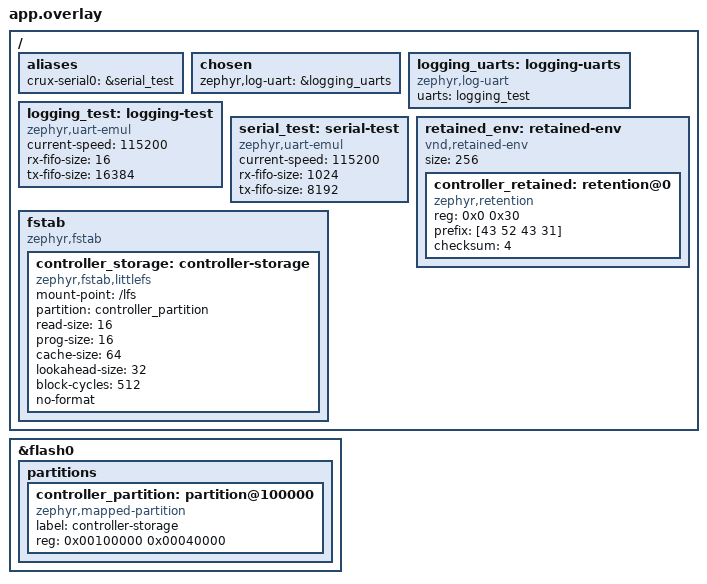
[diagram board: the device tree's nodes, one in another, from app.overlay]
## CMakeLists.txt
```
# SPDX-License-Identifier: Apache-2.0

# The storage scenario of the controller framework on native_sim: LittleFS on the flash simulator, the
# size limit of the application data root (criterion 24), the factory reset with a power cut before
# the erase (criterion 42) and failed logins (criterion 43). The scenario's main() is the application:
# it passes its own descriptor and writes under its data root through Crux File, as a product would.
# This file names no source or include directory of the framework.

cmake_minimum_required(VERSION 3.20.0)
list(APPEND DTS_ROOT "${CMAKE_CURRENT_LIST_DIR}/../common")
find_package(Zephyr REQUIRED HINTS $ENV{ZEPHYR_BASE})
project(controller_framework_storage_native_sim LANGUAGES C)

if(NOT CONFIG_BOARD_NATIVE_SIM OR NOT CONFIG_FAKE_ENTROPY_NATIVE_SIM)
    message(FATAL_ERROR "This scenario is restricted to native_sim: its entropy source is a test source")
endif()
if(NOT CONFIG_CRUX_CONTROLLER_FRAMEWORK_SUPERVISION OR NOT CONFIG_CRUX_CONTROLLER_FRAMEWORK_REBOOT
   OR NOT CONFIG_CRUX_CONTROLLER_FRAMEWORK_MANAGEMENT OR NOT CONFIG_CRUX_FILE_SIMULATOR
   OR NOT CONFIG_FILE_SYSTEM_LITTLEFS OR NOT CONFIG_CRUX_SYSTEM_NATIVE_SIM_WATCHDOG)
    message(FATAL_ERROR "The storage scenario needs supervision, Crux Reboot, web management, LittleFS "
                        "on the flash simulator and the simulated watchdog")
endif()

target_sources(app PRIVATE src/test_storage.c ../common/scenario.c ../common/retained_env.c
    ../common/https.c)
target_include_directories(app PRIVATE ../common)
# crux::security_event: the scenario waits for the event drain before a line that follows events.
target_link_libraries(app PRIVATE controller::framework crux::access crux::file crux::config_service
    crux::credential_store crux::logging crux::security_event)
# Test-only: Crux's account erase resolves to __wrap_crux_credential_erase_accounts in
# src/test_storage.c, which cuts the power in boot 1, before anything is erased, and calls Crux's
# erase in the other boots. GNU ld's --wrap, as the application scenario wraps the TLS start.
target_link_options(app PUBLIC -Wl,--wrap=crux_credential_erase_accounts)
# Test-only: the session creation of Crux Access for channel adapters, which no product reaches, so
# that the test can make an account of the read-only role and save the configuration in the
# administrator's name. PRIVATE to this test image, as in the application scenario.
target_include_directories(app PRIVATE "${ZEPHYR_CRUX_MODULE_DIR}/components/access/adapter")
controller_framework_image()
```

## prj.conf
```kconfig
# SPDX-License-Identifier: Apache-2.0
# The storage scenario of the controller framework on native_sim: LittleFS on the flash simulator,
# the size limit of the application data root (criterion 24), the factory reset with a power cut
# before the erase (criterion 42) and failed logins (criterion 43). Its other values are those of the
# application scenario (tests/framework/application/prj.conf), with no start prerequisite, because
# this scenario degrades storage on purpose.
CONFIG_CRUX_CONTROLLER_FRAMEWORK=y
CONFIG_SNTP=y
CONFIG_CRUX_CONTROLLER_TIME_SERVER="127.0.0.1"

CONFIG_CRUX_SERIAL=y
CONFIG_CRUX_CLI=y
CONFIG_CRUX_CLI_CONSOLE=y
CONFIG_CRUX_CLI_CONSOLE_PRIORITY=11
CONFIG_UART_INTERRUPT_DRIVEN=y
CONFIG_UART_USE_RUNTIME_CONFIGURE=y

CONFIG_STD_C17=y
CONFIG_EMUL=y
CONFIG_UART_EMUL=y
CONFIG_IRQ_OFFLOAD=y
# The web adapter refuses the external libc of native_sim; the management scenario runs on picolibc.
CONFIG_PICOLIBC=y
# One thread of the test runs the start sequence (key generation, signing, the format of the RAM
# disk) and the TLS client. Not measured.
CONFIG_MAIN_STACK_SIZE=32768
CONFIG_HEAP_MEM_POOL_SIZE=32768

# The Mbed TLS profile of app/conf/management.conf, as a copy: this scenario has no Kconfig of the product,
# as in the management scenario. The heap is larger than the product's 120,000 bytes,
# because the TLS client of the test runs in the same process and takes up to one more connection
# and its own handshake. The product declares 120,000 bytes for three server connections of 34,912
# bytes, a handshake of 3,576 bytes and the other PSA users, and 180,000 leaves about 25,000 bytes
# over the worst concurrent case that this process can reach. A paper figure, not measured.
CONFIG_MBEDTLS=y
CONFIG_MBEDTLS_PSA_CRYPTO_C=y
CONFIG_PSA_CRYPTO_PROVIDER_MBEDTLS=y
CONFIG_MBEDTLS_ENABLE_HEAP=y
CONFIG_MBEDTLS_HEAP_SIZE=180000
CONFIG_MBEDTLS_SSL_IN_CONTENT_LEN=16384
CONFIG_MBEDTLS_SSL_OUT_CONTENT_LEN=16384
CONFIG_MBEDTLS_SSL_PROTO_TLS1_2=y
CONFIG_MBEDTLS_SSL_PROTO_TLS1_3=y
CONFIG_MBEDTLS_SSL_TLS1_3_KEY_EXCHANGE_MODE_EPHEMERAL_ENABLED=y
CONFIG_MBEDTLS_KEY_EXCHANGE_ECDHE_ECDSA_ENABLED=y
CONFIG_MBEDTLS_CIPHERSUITE_TLS_ECDHE_ECDSA_WITH_AES_128_GCM_SHA256=y
CONFIG_MBEDTLS_CIPHERSUITE_TLS1_3_AES_128_GCM_SHA256=y
CONFIG_PSA_WANT_ALG_SHA_256=y
CONFIG_PSA_WANT_ECC_SECP_R1_256=y
CONFIG_PSA_WANT_ALG_ECDSA=y
CONFIG_PSA_WANT_ALG_ECDH=y
CONFIG_PSA_WANT_ALG_GCM=y
CONFIG_PSA_WANT_KEY_TYPE_AES=y
CONFIG_PSA_WANT_ALG_HMAC=y
CONFIG_PSA_WANT_KEY_TYPE_HMAC=y
CONFIG_PSA_WANT_ALG_HKDF=y
CONFIG_PSA_WANT_ALG_PBKDF2_HMAC=y
CONFIG_PSA_WANT_ALG_TLS12_PRF=y
CONFIG_PSA_WANT_KEY_TYPE_ECC_PUBLIC_KEY=y
CONFIG_PSA_WANT_KEY_TYPE_ECC_KEY_PAIR_IMPORT=y
CONFIG_PSA_WANT_KEY_TYPE_ECC_KEY_PAIR_EXPORT=y
CONFIG_PSA_WANT_KEY_TYPE_ECC_KEY_PAIR_GENERATE=y
CONFIG_PSA_WANT_KEY_TYPE_ECC_KEY_PAIR_DERIVE=y
CONFIG_MBEDTLS_PK_WRITE_C=y
CONFIG_CRUX_PSA_THREADING=y

# The Crux services, as in app/conf/management.conf. The module selects Thread, Sync and Time for them.
CONFIG_CRUX_ACCESS=y
CONFIG_CRUX_CONFIG_SERVICE=y
CONFIG_CRUX_MGMT_STATUS=y
CONFIG_CRUX_TLS_CERTIFICATE=y
CONFIG_CRUX_WEB=y
CONFIG_CRUX_WEB_SESSION=y
CONFIG_CRUX_WEB_MANAGEMENT=y
CONFIG_CRUX_SYSTEM=y
CONFIG_CRUX_NETIF=y
CONFIG_WATCHDOG=y
CONFIG_HWINFO=y
CONFIG_REBOOT=y

# The listener binds the loopback address, and the TLS client of the test is in the same process. The
# listener opens on Zephyr's own thread, so the client retries its connect.
CONFIG_CRUX_WEB_PORT=443
CONFIG_CRUX_WEB_BIND_ADDRESS="127.0.0.1"
CONFIG_CRUX_WEB_BACKLOG=4
CONFIG_HTTP_SERVER_MAX_CLIENTS=3
CONFIG_HTTP_SERVER_STACK_SIZE=16384
CONFIG_CRUX_WEB_SESSION_WORKER_PRIORITY=11
CONFIG_CRUX_WEB_MANAGEMENT_WORKER_PRIORITY=11
CONFIG_CRUX_SECURITY_EVENT_DRAIN_PRIORITY=11

# The simulator's fake entropy source: test-only, so nothing made here is a secret.
CONFIG_ENTROPY_GENERATOR=y

# Crux File on LittleFS over the flash simulator of native_sim (CONFIG_CRUX_FILE_SIMULATOR), which
# keeps its bytes in a file of the host, so the volume survives the restart of the simulated process
# (criteria 24 and 42 on LittleFS). The first boot finds the flash blank, and the zone formats it.
CONFIG_FLASH=y
CONFIG_FLASH_MAP=y
CONFIG_FLASH_SIMULATOR=y
CONFIG_FILE_SYSTEM=y
CONFIG_FILE_SYSTEM_MKFS=y
CONFIG_FILE_SYSTEM_LITTLEFS=y
CONFIG_FS_LITTLEFS_NUM_FILES=8
CONFIG_CRUX_FILE_SIMULATOR=y

# The network: Zephyr's loopback interface, TCP and the TLS socket layer, with no host network.
CONFIG_NETWORKING=y
CONFIG_NET_IPV4=y
CONFIG_NET_IPV6=n
CONFIG_NET_TCP=y
CONFIG_NET_UDP=y
CONFIG_NET_SOCKETS=y
CONFIG_NET_DRIVERS=y
CONFIG_NET_LOOPBACK=y
CONFIG_NET_SOCKETS_SOCKOPT_TLS=y
CONFIG_TLS_CREDENTIALS=y
CONFIG_TLS_MAX_CREDENTIALS_NUMBER=4
CONFIG_NET_SOCKETS_TLS_MAX_CONTEXTS=6
CONFIG_ZVFS_OPEN_MAX=48
CONFIG_ZVFS_POLL_MAX=24
CONFIG_ZVFS_EVENTFD=y
CONFIG_NET_MAX_CONTEXTS=32
CONFIG_NET_MAX_CONN=32
CONFIG_NET_PKT_RX_COUNT=64
CONFIG_NET_PKT_TX_COUNT=64
CONFIG_NET_BUF_RX_COUNT=256
CONFIG_NET_BUF_TX_COUNT=256

# Crux Logging writes to an emulated UART, so that the test can read what it wrote.
CONFIG_CRUX_LOGGING=y
CONFIG_SERIAL=y
CONFIG_LOG=y
CONFIG_LOG_MODE_DEFERRED=y
CONFIG_LOG_MODE_OVERFLOW=n
CONFIG_LOG_BLOCK_IN_THREAD=n
CONFIG_LOG_PROCESS_THREAD=y
CONFIG_LOG_PROCESS_THREAD_STACK_SIZE=2048
CONFIG_LOG_PROCESS_THREAD_CUSTOM_PRIORITY=y
CONFIG_LOG_PROCESS_THREAD_PRIORITY=14
CONFIG_LOG_BUFFER_SIZE=8192
CONFIG_LOG_MAX_LEVEL=4
CONFIG_LOG_DEFAULT_LEVEL=0
CONFIG_LOG_RUNTIME_FILTERING=n
CONFIG_LOG_BACKEND_UART=y
CONFIG_LOG_BACKEND_NATIVE_POSIX=n
CONFIG_LOG_BACKEND_UART_ASYNC=n
CONFIG_LOG_PRINTK=n
CONFIG_SHELL_LOG_BACKEND=n
CONFIG_LOG_BACKEND_SHOW_LEVEL=y
CONFIG_LOG_BACKEND_CRLF_NONE=n
CONFIG_THREAD_MONITOR=y
CONFIG_THREAD_NAME=y
# An image with Crux management must not enable the Zephyr shell.
CONFIG_SHELL=n

# Health supervision with the simulated watchdog and the retained region, short timeouts so that
# the scenario stays short, and fault injection. The retained memory and the retention area are
# built without their mutexes, as the base image builds them, because the fatal error handler
# writes the region.
CONFIG_TASK_WDT=y
CONFIG_TASK_WDT_HW_FALLBACK=n
CONFIG_CRUX_REBOOT=y
CONFIG_CRUX_SYSTEM_NATIVE_SIM_WATCHDOG=y
CONFIG_NATIVE_SIM_REBOOT=y
CONFIG_RETAINED_MEM=y
CONFIG_RETAINED_MEM_MUTEX_FORCE_DISABLE=y
CONFIG_RETENTION=y
CONFIG_RETENTION_MUTEX_FORCE_DISABLE=y
CONFIG_CRUX_CONTROLLER_FRAMEWORK_FAULT_INJECTION=y
CONFIG_CRUX_CONTROLLER_WATCHDOG_TIMEOUT_MS=2000
CONFIG_CRUX_CONTROLLER_SUPERVISOR_PERIOD_MS=500
CONFIG_CRUX_CONTROLLER_DEADLINE_COMMAND_LINE_MS=2000
CONFIG_CRUX_CONTROLLER_STABLE_PERIOD_S=3600
CONFIG_MAIN_THREAD_PRIORITY=8

# --- The application ------------------------------------------------------------------------------
# The scenario's own descriptor, with the deadlines of the application scenario and no start
# prerequisite.
CONFIG_CRUX_CONTROLLER_DEADLINE_INIT_MS=2000
CONFIG_CRUX_CONTROLLER_DEADLINE_APPLICATION_MS=1500
CONFIG_CRUX_CONTROLLER_DEADLINE_STOP_MS=1000
CONFIG_CRUX_CONTROLLER_APP_THREAD_STACK=4096
# The run has one fault reset (the power cut); the threshold keeps every boot out of safe mode.
CONFIG_CRUX_CONTROLLER_SAFE_MODE_THRESHOLD=10

# A small limit of the application data root, so that boot 1 fills it with a few files (criterion 24,
# gap C15); a value other than the default (criterion 27).
CONFIG_CRUX_CONTROLLER_APP_ROOT_MAX_BYTES=16384
```

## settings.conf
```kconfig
# SPDX-License-Identifier: Apache-2.0
# A fragment for the build test of criterion 32 (check base-settings-file-sources): Crux's Settings
# File provider of Configuration on the LittleFS volume of the storage scenario. The check configures
# the scenario with it and reads which Settings File sources the build compiles; nothing runs it,
# because the framework does not initialise the provider yet (gap C22).
CONFIG_SETTINGS=y
CONFIG_SETTINGS_FILE=y
CONFIG_SETTINGS_FILE_PATH="/lfs/settings/cfg"
CONFIG_CRUX_CONFIGURATION_SETTINGS_FILE_ANY_FS=y
```

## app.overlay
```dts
/* The devicetree of the storage scenario. As in the application scenario
 * (tests/framework/application/app.overlay): a retained region over the test-only retained memory of
 * ../common, which keeps its bytes across a restart of the simulated process; Crux Logging on an
 * emulated UART that the test reads; and the Crux serial console on a second emulated UART through
 * the alias crux-serial0, which the test types into. Unlike there, the volume of the entry
 * controller_storage is LittleFS on the flash simulator, which keeps its bytes in a file of the host,
 * so the volume survives the restart of the simulated process; the first boot finds it blank. */
/ {
    aliases { crux-serial0 = &serial_test; };
    chosen { zephyr,log-uart = &logging_uarts; };
    logging_uarts: logging-uarts {
        compatible = "zephyr,log-uart";
        uarts = <&logging_test>;
    };
    logging_test: logging-test {
        compatible = "zephyr,uart-emul";
        current-speed = <115200>;
        rx-fifo-size = <16>;
        tx-fifo-size = <16384>;
        status = "okay";
    };
    serial_test: serial-test {
        compatible = "zephyr,uart-emul";
        current-speed = <115200>;
        rx-fifo-size = <1024>;
        /* The status command writes more than 1 KiB at once, and the emulated UART drops the bytes
         * that do not fit (uart_emul_poll_out in Zephyr's drivers/serial/uart_emul.c). */
        tx-fifo-size = <8192>;
        status = "okay";
    };

    retained_env: retained-env {
        compatible = "vnd,retained-env";
        size = <256>;
        status = "okay";
        #address-cells = <1>;
        #size-cells = <1>;

        controller_retained: retention@0 {
            compatible = "zephyr,retention";
            status = "okay";
            reg = <0x0 0x30>;
            prefix = [43 52 43 31];
            checksum = <4>;
        };
    };

    fstab {
        compatible = "zephyr,fstab";
        controller_storage: controller-storage {
            compatible = "zephyr,fstab,littlefs";
            mount-point = "/lfs";
            partition = <&controller_partition>;
            read-size = <16>;
            prog-size = <16>;
            cache-size = <64>;
            lookahead-size = <32>;
            block-cycles = <512>;
            /* Never format on a failed mount: the zone formats only a blank volume, by its policy. */
            no-format;
        };
    };
};

/* 256 KiB in the free upper half of the simulated 2 MiB flash (as Crux's tests/native/file_littlefs
 * places its partition). */
&flash0 {
    partitions {
        controller_partition: partition@100000 {
            compatible = "zephyr,mapped-partition";
            label = "controller-storage";
            reg = <0x00100000 0x00040000>;
        };
    };
};
```

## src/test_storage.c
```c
/* SPDX-License-Identifier: Apache-2.0 */

/* The storage scenario of the controller framework on native_sim. One run, three boots, on LittleFS
 * over the flash simulator, whose file on the host keeps the volume across the restarts. main() is
 * the application: it passes its own descriptor and writes under its data root through Crux File,
 * as a product would. Each boot prints what the console harness of testcase.yaml matches, in order:
 *
 *   1. The blank volume is formatted. The first account is set up on the serial command line. The
 *      application fills its data root until Crux File refuses a write at the size limit; the
 * status service then shows storage degraded and a credential save (a second account) still
 * succeeds (criterion 24, gap C15; the parameter save needs a save provider, gap C22). The
 *      read-only account does not see the factory reset command; the administrator changes its
 *      role and resets its password, then runs the factory reset, and the power is cut before the
 *      account erase (criterion 42). Crux's security events of these steps (first-account setup,
 *      login, account creation, logout, role change and password reset) are in the log before the
 *      scenario line that follows them (criterion 44, without persistence).
 *   2. The accounts are still in place: the administrator logs in. The data root is empty. The
 *      factory reset runs again and completes.
 *   3. First-account setup is open again, the data root is empty, and the device identity was kept.
 *      Wrong passwords on the serial command line and on web management are delayed and recorded as
 *      security events (criterion 43).
 */

#include <stdbool.h>
#include <stddef.h>
#include <stdint.h>
#include <stdio.h>
#include <string.h>

#include <controller/framework.h>
#include <crux/access.h>
#include <crux/config_service.h>
#include <crux/credential_store.h>
#include <crux/file.h>
#include <crux/security_event.h>

#include <crux_access_adapter.h>
#include <zephyr/kernel.h>
#include <zephyr/sys/reboot.h>

#include "https.h"
#include "scenario.h"

#define USER "operator"
#define PASSWORD "storage scenario password"
#define READER "reader"
#define READER_ROLE "read-only"
#define READER_PASSWORD "storage scenario reader"
#define READER_RESET_PASSWORD "storage scenario reader reset"
#define WRONG_PASSWORD "not the password at all"
/* The data root (CONFIG_CRUX_CONTROLLER_APP_ROOT_MAX_BYTES is 16384 here) and one LittleFS block.
 */
#define FILE_BYTES 4096u
#define FILES_MAX 16
#define STATUS_POLLS 20
#define LOGIN_ATTEMPTS 10
#define DRAIN_POLLS 200

static int boot;
static controller_app_context_t *app_context;

static void fail(const char *what)
{
    char text[160];

    (void)snprintf(text, sizeof text, "storage scenario FAILED: %s", what);
    scenario_say(text);
}

static bool expect(const char *text)
{
    if (!scenario_console_expect(text)) {
        fail(text);
        return false;
    }
    return true;
}

/* --- the application: four entries that do nothing but succeed --- */

static int app_init(controller_app_context_t *context)
{
    app_context = context;
    return 0;
}

static int app_start(controller_app_context_t *context)
{
    (void)context;
    return 0;
}

static int app_stop(controller_app_context_t *context, controller_app_stop_reason_t reason)
{
    (void)context;
    (void)reason;
    return 0;
}

static void app_safe_state(controller_app_context_t *context)
{
    (void)context;
}

static const controller_app_t app = {app_init, app_start, app_stop, app_safe_state, NULL};

/* --- the power cut of boot 1 --- */

crux_credential_result_t __real_crux_credential_erase_accounts(void);
crux_credential_result_t __wrap_crux_credential_erase_accounts(void);

/* Boot 1: the power goes before the erase writes anything; a restart of the simulated process
 * stands in for the cut (no marker is written, and the volume keeps what was written before). */
crux_credential_result_t __wrap_crux_credential_erase_accounts(void)
{
    if (boot == 1) {
        scenario_say("storage scenario: power cut before the account erase");
        sys_reboot(SYS_REBOOT_COLD);
    }
    return __real_crux_credential_erase_accounts();
}

/* Wait until Crux's drain thread has written every security event that the ring admitted, so the
 * next scenario line follows their log lines: scenario_say() flushes the log first. A report of
 * lost records also counts as a written line, so the written lines reach the admitted ones at
 * least. The counts wrap at 2^32, so their difference is compared as signed. */
static bool events_drained(void)
{
    for (int poll = 0; poll < DRAIN_POLLS; poll++) {
        crux_security_event_stats_t stats;

        if (crux_security_event_get_stats(&stats) == CRUX_OK &&
            (int32_t)(stats.delivered + stats.log_errors - stats.emitted) >= 0) {
            return true;
        }
        k_msleep(10);
    }
    fail("the security events to drain");
    return false;
}

/* --- the serial command line --- */

static bool login(const char *user, const char *password)
{
    if (!expect("login: ")) {
        return false;
    }
    scenario_console_type(user);
    if (!expect("password: ")) {
        return false;
    }
    scenario_console_type(password);
    return expect("> ");
}

static bool setup_first_account(void)
{
    if (!expect("login: ")) {
        return false;
    }
    scenario_console_type("!setup");
    if (!expect("new user: ")) {
        return false;
    }
    scenario_console_type(USER);
    if (!expect("password: ")) {
        return false;
    }
    scenario_console_type(PASSWORD);
    if (!expect("repeat: ")) {
        return false;
    }
    scenario_console_type(PASSWORD);
    if (!expect("account created")) {
        return false;
    }
    return login(USER, PASSWORD);
}

static void logout(void)
{
    scenario_console_type("logout");
}

/* The storage health in the status service: the status command, until it shows the value. */
static bool storage_health_is(const char *value)
{
    char item[160];

    (void)snprintf(item, sizeof item,
                   "{\"name\":\"controller.health.storage\",\"status\":\"ok\",\"type\":\"text\","
                   "\"value\":\"%s\"}",
                   value);
    for (int poll = 0; poll < STATUS_POLLS; poll++) {
        scenario_console_type("status");
        if (scenario_console_expect(item)) {
            return expect("> ");
        }
        k_msleep(500);
    }
    fail(item);
    return false;
}

/* --- Crux Access in the administrator's name (no command makes a second account, gap C21) --- */

static bool admin_session(crux_access_session_t *session)
{
    const crux_access_origin_t origin = {CRUX_ACCESS_CHANNEL_SERIAL, {0}, 0u};
    uint32_t retry_after_ms = 0u;

    return crux_access_login_password(USER, PASSWORD, strlen(PASSWORD), &origin, session,
                                      &retry_after_ms) == CRUX_ACCESS_OK;
}

static bool reader_created(void)
{
    crux_access_session_t session = {0u};

    if (!admin_session(&session)) {
        fail("the administrator's session for the read-only account");
        return false;
    }
    const crux_access_result_t created = crux_access_account_create(
        session, READER, READER_ROLE, READER_PASSWORD, strlen(READER_PASSWORD));

    crux_access_logout(&session);
    return created == CRUX_ACCESS_OK;
}

/* --- the application's data root --- */

static int data_root(void)
{
    return controller_app_data_root(app_context);
}

/* Write files of one block until Crux File refuses one; the count of files written. */
static int fill_data_root(crux_file_result_t *refusal)
{
    static uint8_t block[FILE_BYTES];

    memset(block, 0x5a, sizeof block);
    for (int index = 0; index < FILES_MAX; index++) {
        char name[32];
        crux_file_t *file = NULL;
        size_t written = 0u;

        (void)snprintf(name, sizeof name, "fill%02d.bin", index);
        crux_file_result_t result =
            crux_file_open_at((crux_file_root_t)data_root(), name, CRUX_FILE_CREATE_REPLACE, &file);
        if (result == CRUX_FILE_OK) {
            result = crux_file_write(file, block, sizeof block, &written);
            if (result == CRUX_FILE_OK) {
                result = crux_file_sync(file);
            }
            (void)crux_file_close(&file);
        }
        if (result != CRUX_FILE_OK) {
            *refusal = result;
            return index;
        }
    }
    *refusal = CRUX_FILE_OK;
    return FILES_MAX;
}

static bool data_root_empty(void)
{
    crux_file_dir_t *dir = NULL;
    char name[64];
    crux_file_info_t info;
    bool end = false;

    if (crux_file_dir_open((crux_file_root_t)data_root(), &dir) != CRUX_FILE_OK) {
        return false;
    }
    const crux_file_result_t result = crux_file_dir_read(dir, name, sizeof name, &info, &end);

    (void)crux_file_dir_close(&dir);
    return result == CRUX_FILE_OK && end;
}

/* --- the boots --- */

static void boot_1(void)
{
    char text[160];
    crux_file_result_t refusal = CRUX_FILE_OK;

    if (!setup_first_account() || !events_drained()) {
        return;
    }
    scenario_say("storage scenario: first account set up");
    const int written = fill_data_root(&refusal);

    (void)snprintf(text, sizeof text, "storage scenario: data root full after %d files result=%d",
                   written, (int)refusal);
    scenario_say(text);
    if (refusal != CRUX_FILE_ERR_NO_SPACE || written < 1 || written >= FILES_MAX) {
        fail("the size limit of the data root");
        return;
    }
    if (!storage_health_is("degraded")) {
        return;
    }
    scenario_say("storage scenario: the status service shows storage degraded");
    if (!reader_created()) {
        fail("a credential save with the data root full");
        return;
    }
    if (!events_drained()) {
        return;
    }
    scenario_say("storage scenario: a credential save succeeds with the data root full");

    /* A parameter save. This application registers no parameter, so the save has nothing to write
     * and answers OK; a save that writes needs a save provider, which the framework does not
     * initialise yet (gap C22), so criterion 24's parameter save is not shown here. */
    crux_access_session_t session = {0u};
    crux_config_service_save_report_t report;

    memset(&report, 0, sizeof report);
    if (!admin_session(&session)) {
        fail("the administrator's session for the parameter save");
        return;
    }
    const crux_config_service_result_t saved = crux_config_service_save(session, &report);

    crux_access_logout(&session);
    (void)snprintf(text, sizeof text, "storage scenario: parameter save result=%d", (int)saved);
    scenario_say(text);

    /* The read-only account does not see the factory reset; the administrator runs it. */
    logout();
    if (!login(READER, READER_PASSWORD)) {
        return;
    }
    scenario_console_type("factory reset");
    if (!expect("unknown command") || !expect("> ")) {
        return;
    }
    scenario_say("storage scenario: the read-only account cannot run the factory reset");
    logout();
    if (!login(USER, PASSWORD)) {
        return;
    }
    /* Account changes that no command or route makes in the base image (gap C21), in the
     * administrator's name, for their security events. The factory reset erases the account. */
    if (!admin_session(&session)) {
        fail("the administrator's session for the account changes");
        return;
    }
    const crux_access_result_t role =
        crux_access_account_set_role(session, READER, "administrator");
    const crux_access_result_t reset = crux_access_account_reset_password(
        session, READER, READER_RESET_PASSWORD, strlen(READER_RESET_PASSWORD));

    crux_access_logout(&session);
    if (role != CRUX_ACCESS_OK || reset != CRUX_ACCESS_OK) {
        (void)snprintf(text, sizeof text, "the account changes role=%d reset=%d", (int)role,
                       (int)reset);
        fail(text);
        return;
    }
    if (!events_drained()) {
        return;
    }
    scenario_say("storage scenario: the role and the password of an account changed");
    scenario_console_type("factory reset");
    if (!expect("restart requested")) {
        return;
    }
    scenario_say("storage scenario: factory reset requested");
}

static void boot_2(void)
{
    if (!expect("login: ")) {
        return;
    }
    /* The console asks for the account before it says that setup is closed. */
    scenario_console_type("!setup");
    if (!expect("new user: ")) {
        return;
    }
    scenario_console_type("intruder");
    if (!expect("password: ")) {
        return;
    }
    scenario_console_type(PASSWORD);
    if (!expect("repeat: ")) {
        return;
    }
    scenario_console_type(PASSWORD);
    if (!expect("setup not available")) {
        return;
    }
    if (!login(USER, PASSWORD)) {
        return;
    }
    scenario_say("storage scenario: the accounts are still in place after the power cut");
    if (!data_root_empty()) {
        fail("an empty data root after the power cut");
        return;
    }
    scenario_say("storage scenario: the data root is empty");
    scenario_console_type("factory reset");
    if (!expect("restart requested")) {
        return;
    }
    scenario_say("storage scenario: factory reset requested again");
}

/* Wrong passwords on the serial command line until the console answers with a delay. */
static bool serial_login_delayed(void)
{
    for (int attempt = 0; attempt < LOGIN_ATTEMPTS; attempt++) {
        if (!expect("login: ")) {
            return false;
        }
        scenario_console_type("nobody");
        if (!expect("password: ")) {
            return false;
        }
        scenario_console_type(WRONG_PASSWORD);
        /* A refused password answers "login failed" at once; inside the delay window the console
         * answers "try again in N s" instead, so the next attempt must come quickly. */
        const int answer = scenario_console_expect_either("try again in ", "login failed");

        if (answer == 1) {
            return true;
        }
        if (answer == 0) {
            return false;
        }
    }
    return false;
}

/* Wrong passwords on web management until the session routes answer "retry later". */
static bool web_login_delayed(void)
{
    static char response[4096];
    char body[160];

    (void)snprintf(body, sizeof body, "{\"user\":\"nobody-web\",\"password\":\"%s\"}",
                   WRONG_PASSWORD);
    for (int attempt = 0; attempt < LOGIN_ATTEMPTS; attempt++) {
        const int status =
            https_request("POST", "/api/v1/session",
                          "Origin: https://" HTTPS_HOST "\r\nContent-Type: application/json\r\n",
                          body, response, sizeof response);

        if (status == 429 || strstr(response, "retry_later") != NULL) {
            return true;
        }
        /* An accepted attempt is checked on the session worker; its result can say it too. */
        const char *start = status == 202 ? strstr(response, "{\"id\":\"") : NULL;

        if (start != NULL) {
            char path[160];

            start += strlen("{\"id\":\"");
            (void)snprintf(path, sizeof path, "/api/v1/session/attempt/%.*s",
                           (int)strcspn(start, "\""), start);
            for (int poll = 0; poll < 20; poll++) {
                const int result = https_request("GET", path, "X-Crux-Request: 1\r\n", NULL,
                                                 response, sizeof response);

                if (result == 429 || strstr(response, "retry_later") != NULL) {
                    return true;
                }
                if (result != 200 || strstr(response, "\"state\":\"pending\"") == NULL) {
                    break;
                }
                k_msleep(100);
            }
        }
        /* The attempt is checked on the session worker; give it time before the next one. */
        k_msleep(300);
    }
    return false;
}

static void boot_3(void)
{
    if (!setup_first_account()) {
        return;
    }
    scenario_say("storage scenario: first-account setup is open after the factory reset");
    if (!data_root_empty()) {
        fail("an empty data root after the factory reset");
        return;
    }
    scenario_say("storage scenario: the data root is empty after the factory reset");
    scenario_console_type("status");
    if (!expect("{\"name\":\"controller.certificate\",\"status\":\"ok\",\"type\":\"text\","
                "\"value\":\"stored\"}") ||
        !expect("> ")) {
        return;
    }
    scenario_say("storage scenario: the device identity was kept");
    logout();
    if (!serial_login_delayed()) {
        fail("a delayed login on the serial command line");
        return;
    }
    scenario_say("storage scenario: the serial command line delays failed logins");
    if (!web_login_delayed()) {
        fail("a delayed login on web management");
        return;
    }
    scenario_say("storage scenario: web management delays failed logins");
    /* Let the security event thread drain the events to the log before the last line. */
    k_msleep(2000);
    scenario_say("storage scenario done");
}

int main(void)
{
    char text[64];

    boot = scenario_boot_number();
    scenario_forward_log();
    (void)snprintf(text, sizeof text, "storage scenario boot %d", boot);
    scenario_say(text);
    if (controller_framework_start(&app) != CONTROLLER_FRAMEWORK_OK) {
        fail("the start function");
    }
    switch (boot) {
    case 1:
        boot_1();
        break;
    case 2:
        boot_2();
        break;
    case 3:
        boot_3();
        break;
    default:
        fail("more boots than planned");
        break;
    }
    for (;;) {
        k_sleep(K_FOREVER);
    }
    return 0;
}
```
